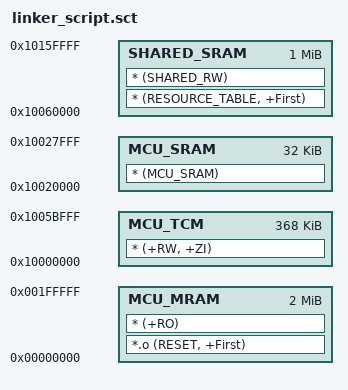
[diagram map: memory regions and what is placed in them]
;******************************************************************************
;
; Scatter file for Keil linker configuration.
;
;******************************************************************************
LR_1 0x00000000
{
    MCU_MRAM 0x00000000 0x00200000
    {
        *.o (RESET, +First)
        * (+RO)
    }

    MCU_TCM 0x10000000 0x0005C000
    {
        * (+RW, +ZI)
    }

    MCU_SRAM 0x10020000 0x00008000
    {
        * (MCU_SRAM)
    }

    SHARED_SRAM 0x10060000 0x00100000
    {
        * (RESOURCE_TABLE, +First)
        * (SHARED_RW)
    }
}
